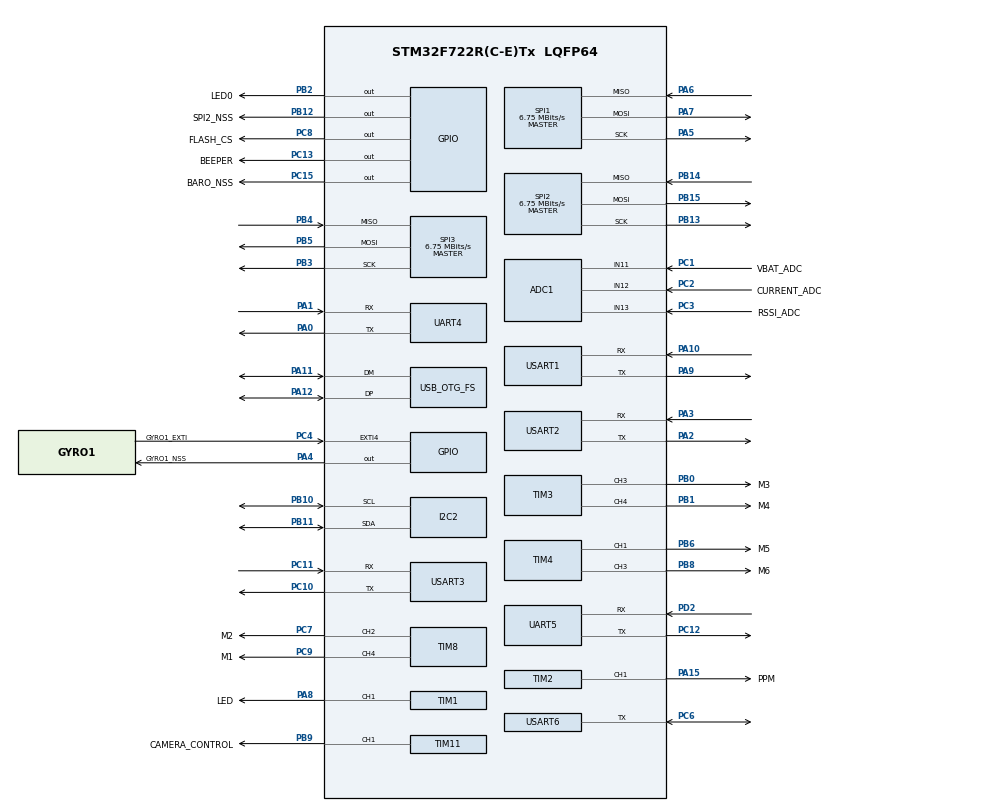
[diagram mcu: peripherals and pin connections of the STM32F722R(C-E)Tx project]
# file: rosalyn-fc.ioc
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ADC1.Channel-1\#ChannelRegularConversion=ADC_CHANNEL_11
ADC1.NbrOfConversionFlag=1
ADC1.Rank-1\#ChannelRegularConversion=1
ADC1.SamplingTime-1\#ChannelRegularConversion=ADC_SAMPLETIME_3CYCLES
ADC1.master=1
CORTEX_M7.ART_ACCLERATOR_ENABLE=1
CORTEX_M7.CPU_DCache=Enabled
CORTEX_M7.CPU_ICache=Enabled
CORTEX_M7.PREFETCH_ENABLE=1
I2C2.Timing=0x20404768
Mcu.Family=STM32F7
Mcu.Name=STM32F722R(C-E)Tx
Mcu.Package=LQFP64
NVIC.OTG_FS_IRQn=true\:0\:0\:false\:false\:true\:false\:true
NVIC.PriorityGroup=NVIC_PRIORITYGROUP_4
PA0-WKUP.Mode=Asynchronous
PA0-WKUP.Signal=UART4_TX
PA1.Mode=Asynchronous
PA1.Signal=UART4_RX
PA10.Mode=Asynchronous
PA10.Signal=USART1_RX
PA11.Mode=Device_Only
PA11.Signal=USB_OTG_FS_DM
PA12.Mode=Device_Only
PA12.Signal=USB_OTG_FS_DP
PA13.Mode=Serial_Wire
PA13.Signal=SYS_JTMS-SWDIO
PA14.Mode=Serial_Wire
PA14.Signal=SYS_JTCK-SWCLK
PA15.GPIO_Label=PPM
PA15.Signal=S_TIM2_CH1_ETR
PA2.Mode=Asynchronous
PA2.Signal=USART2_TX
PA3.Mode=Asynchronous
PA3.Signal=USART2_RX
PA4.GPIO_Label=GYRO1_NSS
PA4.PinState=GPIO_PIN_SET
PA4.Signal=GPIO_Output
PA5.Mode=Full_Duplex_Master
PA5.Signal=SPI1_SCK
PA6.GPIO_PuPd=GPIO_PULLUP
PA6.Mode=Full_Duplex_Master
PA6.Signal=SPI1_MISO
PA7.Mode=Full_Duplex_Master
PA7.Signal=SPI1_MOSI
PA8.GPIO_Label=LED
PA8.Signal=S_TIM1_CH1
PA9.Mode=Asynchronous
PA9.Signal=USART1_TX
PB0.GPIO_Label=M3
PB0.Signal=S_TIM3_CH3
PB1.GPIO_Label=M4
PB1.Signal=S_TIM3_CH4
PB10.Mode=I2C
PB10.Signal=I2C2_SCL
PB11.Mode=I2C
PB11.Signal=I2C2_SDA
PB12.GPIO_Label=SPI2_NSS
PB12.PinState=GPIO_PIN_SET
PB12.Signal=GPIO_Output
PB13.Mode=Full_Duplex_Master
PB13.Signal=SPI2_SCK
PB14.GPIO_PuPd=GPIO_PULLUP
PB14.Mode=Full_Duplex_Master
PB14.Signal=SPI2_MISO
PB15.Mode=Full_Duplex_Master
PB15.Signal=SPI2_MOSI
PB2.GPIO_Label=LED0
PB2.PinState=GPIO_PIN_SET
PB2.Signal=GPIO_Output
PB3.Mode=Full_Duplex_Master
PB3.Signal=SPI3_SCK
PB4.GPIO_PuPd=GPIO_PULLUP
PB4.Mode=Full_Duplex_Master
PB4.Signal=SPI3_MISO
PB5.Mode=Full_Duplex_Master
PB5.Signal=SPI3_MOSI
PB6.GPIO_Label=M5
PB6.Signal=S_TIM4_CH1
PB8.GPIO_Label=M6
PB8.Signal=S_TIM4_CH3
PB9.GPIO_Label=CAMERA_CONTROL
PB9.Signal=S_TIM11_CH1
PC1.GPIO_Label=VBAT_ADC
PC1.Signal=ADCx_IN11
PC10.Mode=Asynchronous
PC10.Signal=USART3_TX
PC11.Mode=Asynchronous
PC11.Signal=USART3_RX
PC12.Mode=Asynchronous
PC12.Signal=UART5_TX
PC13.GPIO_Label=BEEPER
PC13.Signal=GPIO_Output
PC15-OSC32_OUT.GPIO_Label=BARO_NSS
PC15-OSC32_OUT.PinState=GPIO_PIN_SET
PC15-OSC32_OUT.Signal=GPIO_Output
PC2.GPIO_Label=CURRENT_ADC
PC2.Signal=ADCx_IN12
PC3.GPIO_Label=RSSI_ADC
PC3.Signal=ADCx_IN13
PC4.GPIO_Label=GYRO1_EXTI
PC4.Signal=GPXTI4
PC6.Mode=Half_duplex(single_wire_mode)
PC6.Signal=USART6_TX
PC7.GPIO_Label=M2
PC7.Signal=S_TIM8_CH2
PC8.GPIO_Label=FLASH_CS
PC8.PinState=GPIO_PIN_SET
PC8.Signal=GPIO_Output
PC9.GPIO_Label=M1
PC9.Signal=S_TIM8_CH4
PD2.Mode=Asynchronous
PD2.Signal=UART5_RX
PH0-OSC_IN.Mode=HSE-External-Oscillator
PH0-OSC_IN.Signal=RCC_OSC_IN
PH1-OSC_OUT.Mode=HSE-External-Oscillator
PH1-OSC_OUT.Signal=RCC_OSC_OUT
ProjectManager.HeapSize=0x200
ProjectManager.StackSize=0x400
ProjectManager.TargetToolchain=STM32CubeIDE
RCC.AHBFreq_Value=216000000
RCC.APB1CLKDivider=RCC_HCLK_DIV4
RCC.APB1Freq_Value=54000000
RCC.APB1TimFreq_Value=108000000
RCC.APB2CLKDivider=RCC_HCLK_DIV2
RCC.APB2Freq_Value=108000000
RCC.APB2TimFreq_Value=216000000
RCC.CortexFreq_Value=216000000
RCC.HCLKFreq_Value=216000000
RCC.HSE_VALUE=8000000
RCC.HSI_VALUE=16000000
RCC.LSE_VALUE=32768
RCC.PLLM=4
RCC.PLLN=216
RCC.PLLQ=9
RCC.SYSCLKFreq_VALUE=216000000
RCC.SYSCLKSource=RCC_SYSCLKSOURCE_PLLCLK
RCC.USBFreq_Value=48000000
RCC.VCOOutputFreq_Value=432000000
SH.ADCx_IN11.0=ADC1_IN11,IN11
SH.ADCx_IN12.0=ADC1_IN12,IN12
SH.ADCx_IN13.0=ADC1_IN13,IN13
SH.S_TIM11_CH1.0=TIM11_CH1,PWM Generation1 CH1
SH.S_TIM1_CH1.0=TIM1_CH1,PWM Generation1 CH1
SH.S_TIM2_CH1_ETR.0=TIM2_CH1,PWM Generation1 CH1
SH.S_TIM3_CH3.0=TIM3_CH3,PWM Generation3 CH3
SH.S_TIM3_CH4.0=TIM3_CH4,PWM Generation4 CH4
SH.S_TIM4_CH1.0=TIM4_CH1,PWM Generation1 CH1
SH.S_TIM4_CH3.0=TIM4_CH3,PWM Generation3 CH3
SH.S_TIM8_CH2.0=TIM8_CH2,PWM Generation2 CH2
SH.S_TIM8_CH4.0=TIM8_CH4,PWM Generation4 CH4
SPI1.BaudRatePrescaler=SPI_BAUDRATEPRESCALER_16
SPI1.CalculateBaudRate=6.75 MBits/s
SPI1.DataSize=SPI_DATASIZE_8BIT
SPI1.Direction=SPI_DIRECTION_2LINES
SPI1.Mode=SPI_MODE_MASTER
SPI1.VirtualType=VM_MASTER
SPI2.BaudRatePrescaler=SPI_BAUDRATEPRESCALER_8
SPI2.CalculateBaudRate=6.75 MBits/s
SPI2.DataSize=SPI_DATASIZE_8BIT
SPI2.Direction=SPI_DIRECTION_2LINES
SPI2.Mode=SPI_MODE_MASTER
SPI2.VirtualType=VM_MASTER
SPI3.BaudRatePrescaler=SPI_BAUDRATEPRESCALER_8
SPI3.CalculateBaudRate=6.75 MBits/s
SPI3.DataSize=SPI_DATASIZE_8BIT
SPI3.Direction=SPI_DIRECTION_2LINES
SPI3.Mode=SPI_MODE_MASTER
SPI3.VirtualType=VM_MASTER
TIM1.Channel-PWM\ Generation1\ CH1=TIM_CHANNEL_1
TIM11.Channel=TIM_CHANNEL_1
TIM2.Channel-PWM\ Generation1\ CH1=TIM_CHANNEL_1
TIM3.Channel-PWM\ Generation3\ CH3=TIM_CHANNEL_3
TIM3.Channel-PWM\ Generation4\ CH4=TIM_CHANNEL_4
TIM4.Channel-PWM\ Generation1\ CH1=TIM_CHANNEL_1
TIM4.Channel-PWM\ Generation3\ CH3=TIM_CHANNEL_3
TIM8.Channel-PWM\ Generation2\ CH2=TIM_CHANNEL_2
TIM8.Channel-PWM\ Generation4\ CH4=TIM_CHANNEL_4
USART1.VirtualMode-Asynchronous=VM_ASYNC
USART2.VirtualMode-Asynchronous=VM_ASYNC
USART3.VirtualMode-Asynchronous=VM_ASYNC
USART6.VirtualMode=VM_ASYNC
USB_DEVICE.CLASS_NAME_FS=CDC
USB_DEVICE.VirtualMode-CDC_FS=Cdc
USB_DEVICE.VirtualModeFS=Cdc_FS
USB_OTG_FS.VirtualMode=Device_Only
VP_ADC1_TempSens_Input.Mode=IN-TempSens
VP_ADC1_Vref_Input.Mode=IN-Vrefint
VP_TIM11_VS_ClockSourceINT.Mode=Enable_Timer
VP_USB_DEVICE_VS_USB_DEVICE_CDC_FS.Mode=CDC_FS
board=custom

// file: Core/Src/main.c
/* USER CODE BEGIN Header */
/**
  ******************************************************************************
  * @file           : main.c
  * @brief          : Main program body
  ******************************************************************************
  * @attention
  *
  * <h2><center>&copy; Copyright (c) 2020 STMicroelectronics.
  * All rights reserved.</center></h2>
  *
  * This software component is licensed by ST under BSD 3-Clause license,
  * the "License"; You may not use this file except in compliance with the
  * License. You may obtain a copy of the License at:
  *                        opensource.org/licenses/BSD-3-Clause
  *
  ******************************************************************************
  */
/* USER CODE END Header */
#include "main.h"
#include "usb_device.h"

void SystemClock_Config(void);
static void MX_GPIO_Init(void);
static void MX_SPI1_Init(void);
static void MX_SPI2_Init(void);
static void MX_TIM1_Init(void);
static void MX_TIM3_Init(void);
static void MX_TIM4_Init(void);
static void MX_TIM8_Init(void);
static void MX_TIM11_Init(void);
static void MX_UART4_Init(void);
static void MX_UART5_Init(void);
static void MX_USART1_UART_Init(void);
static void MX_ADC1_Init(void);
static void MX_SPI3_Init(void);
static void MX_USART2_UART_Init(void);
static void MX_USART3_UART_Init(void);
static void MX_I2C2_Init(void);
static void MX_TIM2_Init(void);
static void MX_USART6_UART_Init(void);

int main(void)
{

  /* Enable I-Cache---------------------------------------------------------*/
  SCB_EnableICache();

  /* Enable D-Cache---------------------------------------------------------*/
  SCB_EnableDCache();

  /* MCU Configuration--------------------------------------------------------*/

  /* Reset of all peripherals, Initializes the Flash interface and the Systick. */
  HAL_Init();

  /* Configure the system clock */
  SystemClock_Config();

  /* Initialize all configured peripherals */
  MX_GPIO_Init();
  MX_SPI1_Init();
  MX_SPI2_Init();
  MX_TIM1_Init();
  MX_TIM3_Init();
  MX_TIM4_Init();
  MX_TIM8_Init();
  MX_TIM11_Init();
  MX_UART4_Init();
  MX_UART5_Init();
  MX_USART1_UART_Init();
  MX_ADC1_Init();
  MX_SPI3_Init();
  MX_USART2_UART_Init();
  MX_USART3_UART_Init();
  MX_I2C2_Init();
  MX_TIM2_Init();
  MX_USB_DEVICE_Init();
  MX_USART6_UART_Init();
  /* USER CODE BEGIN 2 */
  extern void RosalynFcSetup( void );
  RosalynFcSetup();
  /* USER CODE END 2 */

  /* Infinite loop */
  while (1)
  {

    /* USER CODE BEGIN 3 */
    extern void RosalynFcLoop( void );
    RosalynFcLoop();
  }
  /* USER CODE END 3 */
}

void SystemClock_Config(void)
{
  LL_FLASH_SetLatency(LL_FLASH_LATENCY_7);
  while(LL_FLASH_GetLatency()!= LL_FLASH_LATENCY_7)
  {
  }
  LL_PWR_SetRegulVoltageScaling(LL_PWR_REGU_VOLTAGE_SCALE1);
  LL_PWR_EnableOverDriveMode();
  LL_RCC_HSE_Enable();

   /* Wait till HSE is ready */
  while(LL_RCC_HSE_IsReady() != 1)
  {

  }
  LL_RCC_PLL_ConfigDomain_SYS(LL_RCC_PLLSOURCE_HSE, LL_RCC_PLLM_DIV_4, 216, LL_RCC_PLLP_DIV_2);
  LL_RCC_PLL_ConfigDomain_48M(LL_RCC_PLLSOURCE_HSE, LL_RCC_PLLM_DIV_4, 216, LL_RCC_PLLQ_DIV_9);
  LL_RCC_PLL_Enable();

   /* Wait till PLL is ready */
  while(LL_RCC_PLL_IsReady() != 1)
  {

  }
  LL_RCC_SetAHBPrescaler(LL_RCC_SYSCLK_DIV_1);
  LL_RCC_SetAPB1Prescaler(LL_RCC_APB1_DIV_4);
  LL_RCC_SetAPB2Prescaler(LL_RCC_APB2_DIV_2);
  LL_RCC_SetSysClkSource(LL_RCC_SYS_CLKSOURCE_PLL);

   /* Wait till System clock is ready */
  while(LL_RCC_GetSysClkSource() != LL_RCC_SYS_CLKSOURCE_STATUS_PLL)
  {

  }
  LL_SetSystemCoreClock(216000000);

   /* Update the time base */
  if (HAL_InitTick (TICK_INT_PRIORITY) != HAL_OK)
  {
    Error_Handler();
  }
  LL_RCC_SetUSBClockSource(LL_RCC_USB_CLKSOURCE_PLL);
  LL_RCC_SetUSARTClockSource(LL_RCC_USART1_CLKSOURCE_PCLK2);
  LL_RCC_SetUSARTClockSource(LL_RCC_USART2_CLKSOURCE_PCLK1);
  LL_RCC_SetUSARTClockSource(LL_RCC_USART3_CLKSOURCE_PCLK1);
  LL_RCC_SetUSARTClockSource(LL_RCC_USART6_CLKSOURCE_PCLK2);
  LL_RCC_SetUARTClockSource(LL_RCC_UART4_CLKSOURCE_PCLK1);
  LL_RCC_SetUARTClockSource(LL_RCC_UART5_CLKSOURCE_PCLK1);
  LL_RCC_SetI2CClockSource(LL_RCC_I2C2_CLKSOURCE_PCLK1);
}

static void MX_ADC1_Init(void)
{

  LL_ADC_InitTypeDef ADC_InitStruct = {0};
  LL_ADC_REG_InitTypeDef ADC_REG_InitStruct = {0};
  LL_ADC_CommonInitTypeDef ADC_CommonInitStruct = {0};

  LL_GPIO_InitTypeDef GPIO_InitStruct = {0};

  /* Peripheral clock enable */
  LL_APB2_GRP1_EnableClock(LL_APB2_GRP1_PERIPH_ADC1);

  LL_AHB1_GRP1_EnableClock(LL_AHB1_GRP1_PERIPH_GPIOC);
  /**ADC1 GPIO Configuration
  PC1   ------> ADC1_IN11
  PC2   ------> ADC1_IN12
  PC3   ------> ADC1_IN13
  */
  GPIO_InitStruct.Pin = VBAT_ADC_Pin;
  GPIO_InitStruct.Mode = LL_GPIO_MODE_ANALOG;
  GPIO_InitStruct.Pull = LL_GPIO_PULL_NO;
  LL_GPIO_Init(VBAT_ADC_GPIO_Port, &GPIO_InitStruct);

  GPIO_InitStruct.Pin = CURRENT_ADC_Pin;
  GPIO_InitStruct.Mode = LL_GPIO_MODE_ANALOG;
  GPIO_InitStruct.Pull = LL_GPIO_PULL_NO;
  LL_GPIO_Init(CURRENT_ADC_GPIO_Port, &GPIO_InitStruct);

  GPIO_InitStruct.Pin = RSSI_ADC_Pin;
  GPIO_InitStruct.Mode = LL_GPIO_MODE_ANALOG;
  GPIO_InitStruct.Pull = LL_GPIO_PULL_NO;
  LL_GPIO_Init(RSSI_ADC_GPIO_Port, &GPIO_InitStruct);

  /** Common config
  */
  ADC_InitStruct.Resolution = LL_ADC_RESOLUTION_12B;
  ADC_InitStruct.DataAlignment = LL_ADC_DATA_ALIGN_RIGHT;
  ADC_InitStruct.SequencersScanMode = LL_ADC_SEQ_SCAN_DISABLE;
  LL_ADC_Init(ADC1, &ADC_InitStruct);
  ADC_REG_InitStruct.TriggerSource = LL_ADC_REG_TRIG_SOFTWARE;
  ADC_REG_InitStruct.SequencerLength = LL_ADC_REG_SEQ_SCAN_DISABLE;
  ADC_REG_InitStruct.SequencerDiscont = LL_ADC_REG_SEQ_DISCONT_DISABLE;
  ADC_REG_InitStruct.ContinuousMode = LL_ADC_REG_CONV_SINGLE;
  ADC_REG_InitStruct.DMATransfer = LL_ADC_REG_DMA_TRANSFER_NONE;
  LL_ADC_REG_Init(ADC1, &ADC_REG_InitStruct);
  LL_ADC_REG_SetFlagEndOfConversion(ADC1, LL_ADC_REG_FLAG_EOC_UNITARY_CONV);
  ADC_CommonInitStruct.CommonClock = LL_ADC_CLOCK_SYNC_PCLK_DIV4;
  ADC_CommonInitStruct.Multimode = LL_ADC_MULTI_INDEPENDENT;
  LL_ADC_CommonInit(__LL_ADC_COMMON_INSTANCE(ADC1), &ADC_CommonInitStruct);
  /** Configure Regular Channel
  */
  LL_ADC_REG_SetSequencerRanks(ADC1, LL_ADC_REG_RANK_1, LL_ADC_CHANNEL_11);
  LL_ADC_SetChannelSamplingTime(ADC1, LL_ADC_CHANNEL_11, LL_ADC_SAMPLINGTIME_3CYCLES);

}

static void MX_I2C2_Init(void)
{

  LL_I2C_InitTypeDef I2C_InitStruct = {0};

  LL_GPIO_InitTypeDef GPIO_InitStruct = {0};

  LL_AHB1_GRP1_EnableClock(LL_AHB1_GRP1_PERIPH_GPIOB);
  /**I2C2 GPIO Configuration
  PB10   ------> I2C2_SCL
  PB11   ------> I2C2_SDA
  */
  GPIO_InitStruct.Pin = LL_GPIO_PIN_10;
  GPIO_InitStruct.Mode = LL_GPIO_MODE_ALTERNATE;
  GPIO_InitStruct.Speed = LL_GPIO_SPEED_FREQ_VERY_HIGH;
  GPIO_InitStruct.OutputType = LL_GPIO_OUTPUT_OPENDRAIN;
  GPIO_InitStruct.Pull = LL_GPIO_PULL_UP;
  GPIO_InitStruct.Alternate = LL_GPIO_AF_4;
  LL_GPIO_Init(GPIOB, &GPIO_InitStruct);

  GPIO_InitStruct.Pin = LL_GPIO_PIN_11;
  GPIO_InitStruct.Mode = LL_GPIO_MODE_ALTERNATE;
  GPIO_InitStruct.Speed = LL_GPIO_SPEED_FREQ_VERY_HIGH;
  GPIO_InitStruct.OutputType = LL_GPIO_OUTPUT_OPENDRAIN;
  GPIO_InitStruct.Pull = LL_GPIO_PULL_UP;
  GPIO_InitStruct.Alternate = LL_GPIO_AF_4;
  LL_GPIO_Init(GPIOB, &GPIO_InitStruct);

  /* Peripheral clock enable */
  LL_APB1_GRP1_EnableClock(LL_APB1_GRP1_PERIPH_I2C2);

  /** I2C Initialization
  */
  LL_I2C_EnableAutoEndMode(I2C2);
  LL_I2C_SetOwnAddress2(I2C2, 0, LL_I2C_OWNADDRESS2_NOMASK);
  LL_I2C_DisableOwnAddress2(I2C2);
  LL_I2C_DisableGeneralCall(I2C2);
  LL_I2C_EnableClockStretching(I2C2);
  I2C_InitStruct.PeripheralMode = LL_I2C_MODE_I2C;
  I2C_InitStruct.Timing = 0x20404768;
  I2C_InitStruct.AnalogFilter = LL_I2C_ANALOGFILTER_ENABLE;
  I2C_InitStruct.DigitalFilter = 0;
  I2C_InitStruct.OwnAddress1 = 0;
  I2C_InitStruct.TypeAcknowledge = LL_I2C_ACK;
  I2C_InitStruct.OwnAddrSize = LL_I2C_OWNADDRESS1_7BIT;
  LL_I2C_Init(I2C2, &I2C_InitStruct);

}

static void MX_SPI1_Init(void)
{

  LL_SPI_InitTypeDef SPI_InitStruct = {0};

  LL_GPIO_InitTypeDef GPIO_InitStruct = {0};

  /* Peripheral clock enable */
  LL_APB2_GRP1_EnableClock(LL_APB2_GRP1_PERIPH_SPI1);

  LL_AHB1_GRP1_EnableClock(LL_AHB1_GRP1_PERIPH_GPIOA);
  /**SPI1 GPIO Configuration
  PA5   ------> SPI1_SCK
  PA6   ------> SPI1_MISO
  PA7   ------> SPI1_MOSI
  */
  GPIO_InitStruct.Pin = LL_GPIO_PIN_5;
  GPIO_InitStruct.Mode = LL_GPIO_MODE_ALTERNATE;
  GPIO_InitStruct.Speed = LL_GPIO_SPEED_FREQ_VERY_HIGH;
  GPIO_InitStruct.OutputType = LL_GPIO_OUTPUT_PUSHPULL;
  GPIO_InitStruct.Pull = LL_GPIO_PULL_NO;
  GPIO_InitStruct.Alternate = LL_GPIO_AF_5;
  LL_GPIO_Init(GPIOA, &GPIO_InitStruct);

  GPIO_InitStruct.Pin = LL_GPIO_PIN_6;
  GPIO_InitStruct.Mode = LL_GPIO_MODE_ALTERNATE;
  GPIO_InitStruct.Speed = LL_GPIO_SPEED_FREQ_VERY_HIGH;
  GPIO_InitStruct.OutputType = LL_GPIO_OUTPUT_PUSHPULL;
  GPIO_InitStruct.Pull = LL_GPIO_PULL_UP;
  GPIO_InitStruct.Alternate = LL_GPIO_AF_5;
  LL_GPIO_Init(GPIOA, &GPIO_InitStruct);

  GPIO_InitStruct.Pin = LL_GPIO_PIN_7;
  GPIO_InitStruct.Mode = LL_GPIO_MODE_ALTERNATE;
  GPIO_InitStruct.Speed = LL_GPIO_SPEED_FREQ_VERY_HIGH;
  GPIO_InitStruct.OutputType = LL_GPIO_OUTPUT_PUSHPULL;
  GPIO_InitStruct.Pull = LL_GPIO_PULL_NO;
  GPIO_InitStruct.Alternate = LL_GPIO_AF_5;
  LL_GPIO_Init(GPIOA, &GPIO_InitStruct);

  /* SPI1 parameter configuration*/
  SPI_InitStruct.TransferDirection = LL_SPI_FULL_DUPLEX;
  SPI_InitStruct.Mode = LL_SPI_MODE_MASTER;
  SPI_InitStruct.DataWidth = LL_SPI_DATAWIDTH_8BIT;
  SPI_InitStruct.ClockPolarity = LL_SPI_POLARITY_LOW;
  SPI_InitStruct.ClockPhase = LL_SPI_PHASE_1EDGE;
  SPI_InitStruct.NSS = LL_SPI_NSS_SOFT;
  SPI_InitStruct.BaudRate = LL_SPI_BAUDRATEPRESCALER_DIV16;
  SPI_InitStruct.BitOrder = LL_SPI_MSB_FIRST;
  SPI_InitStruct.CRCCalculation = LL_SPI_CRCCALCULATION_DISABLE;
  SPI_InitStruct.CRCPoly = 7;
  LL_SPI_Init(SPI1, &SPI_InitStruct);
  LL_SPI_SetStandard(SPI1, LL_SPI_PROTOCOL_MOTOROLA);
  LL_SPI_EnableNSSPulseMgt(SPI1);

}

static void MX_SPI2_Init(void)
{

  LL_SPI_InitTypeDef SPI_InitStruct = {0};

  LL_GPIO_InitTypeDef GPIO_InitStruct = {0};

  /* Peripheral clock enable */
  LL_APB1_GRP1_EnableClock(LL_APB1_GRP1_PERIPH_SPI2);

  LL_AHB1_GRP1_EnableClock(LL_AHB1_GRP1_PERIPH_GPIOB);
  /**SPI2 GPIO Configuration
  PB13   ------> SPI2_SCK
  PB14   ------> SPI2_MISO
  PB15   ------> SPI2_MOSI
  */
  GPIO_InitStruct.Pin = LL_GPIO_PIN_13;
  GPIO_InitStruct.Mode = LL_GPIO_MODE_ALTERNATE;
  GPIO_InitStruct.Speed = LL_GPIO_SPEED_FREQ_VERY_HIGH;
  GPIO_InitStruct.OutputType = LL_GPIO_OUTPUT_PUSHPULL;
  GPIO_InitStruct.Pull = LL_GPIO_PULL_NO;
  GPIO_InitStruct.Alternate = LL_GPIO_AF_5;
  LL_GPIO_Init(GPIOB, &GPIO_InitStruct);

  GPIO_InitStruct.Pin = LL_GPIO_PIN_14;
  GPIO_InitStruct.Mode = LL_GPIO_MODE_ALTERNATE;
  GPIO_InitStruct.Speed = LL_GPIO_SPEED_FREQ_VERY_HIGH;
  GPIO_InitStruct.OutputType = LL_GPIO_OUTPUT_PUSHPULL;
  GPIO_InitStruct.Pull = LL_GPIO_PULL_UP;
  GPIO_InitStruct.Alternate = LL_GPIO_AF_5;
  LL_GPIO_Init(GPIOB, &GPIO_InitStruct);

  GPIO_InitStruct.Pin = LL_GPIO_PIN_15;
  GPIO_InitStruct.Mode = LL_GPIO_MODE_ALTERNATE;
  GPIO_InitStruct.Speed = LL_GPIO_SPEED_FREQ_VERY_HIGH;
  GPIO_InitStruct.OutputType = LL_GPIO_OUTPUT_PUSHPULL;
  GPIO_InitStruct.Pull = LL_GPIO_PULL_NO;
  GPIO_InitStruct.Alternate = LL_GPIO_AF_5;
  LL_GPIO_Init(GPIOB, &GPIO_InitStruct);

  /* SPI2 parameter configuration*/
  SPI_InitStruct.TransferDirection = LL_SPI_FULL_DUPLEX;
  SPI_InitStruct.Mode = LL_SPI_MODE_MASTER;
  SPI_InitStruct.DataWidth = LL_SPI_DATAWIDTH_8BIT;
  SPI_InitStruct.ClockPolarity = LL_SPI_POLARITY_LOW;
  SPI_InitStruct.ClockPhase = LL_SPI_PHASE_1EDGE;
  SPI_InitStruct.NSS = LL_SPI_NSS_SOFT;
  SPI_InitStruct.BaudRate = LL_SPI_BAUDRATEPRESCALER_DIV8;
  SPI_InitStruct.BitOrder = LL_SPI_MSB_FIRST;
  SPI_InitStruct.CRCCalculation = LL_SPI_CRCCALCULATION_DISABLE;
  SPI_InitStruct.CRCPoly = 7;
  LL_SPI_Init(SPI2, &SPI_InitStruct);
  LL_SPI_SetStandard(SPI2, LL_SPI_PROTOCOL_MOTOROLA);
  LL_SPI_EnableNSSPulseMgt(SPI2);

}

static void MX_SPI3_Init(void)
{

  LL_SPI_InitTypeDef SPI_InitStruct = {0};

  LL_GPIO_InitTypeDef GPIO_InitStruct = {0};

  /* Peripheral clock enable */
  LL_APB1_GRP1_EnableClock(LL_APB1_GRP1_PERIPH_SPI3);

  LL_AHB1_GRP1_EnableClock(LL_AHB1_GRP1_PERIPH_GPIOB);
  /**SPI3 GPIO Configuration
  PB3   ------> SPI3_SCK
  PB4   ------> SPI3_MISO
  PB5   ------> SPI3_MOSI
  */
  GPIO_InitStruct.Pin = LL_GPIO_PIN_3;
  GPIO_InitStruct.Mode = LL_GPIO_MODE_ALTERNATE;
  GPIO_InitStruct.Speed = LL_GPIO_SPEED_FREQ_VERY_HIGH;
  GPIO_InitStruct.OutputType = LL_GPIO_OUTPUT_PUSHPULL;
  GPIO_InitStruct.Pull = LL_GPIO_PULL_NO;
  GPIO_InitStruct.Alternate = LL_GPIO_AF_6;
  LL_GPIO_Init(GPIOB, &GPIO_InitStruct);

  GPIO_InitStruct.Pin = LL_GPIO_PIN_4;
  GPIO_InitStruct.Mode = LL_GPIO_MODE_ALTERNATE;
  GPIO_InitStruct.Speed = LL_GPIO_SPEED_FREQ_VERY_HIGH;
  GPIO_InitStruct.OutputType = LL_GPIO_OUTPUT_PUSHPULL;
  GPIO_InitStruct.Pull = LL_GPIO_PULL_UP;
  GPIO_InitStruct.Alternate = LL_GPIO_AF_6;
  LL_GPIO_Init(GPIOB, &GPIO_InitStruct);

  GPIO_InitStruct.Pin = LL_GPIO_PIN_5;
  GPIO_InitStruct.Mode = LL_GPIO_MODE_ALTERNATE;
  GPIO_InitStruct.Speed = LL_GPIO_SPEED_FREQ_VERY_HIGH;
  GPIO_InitStruct.OutputType = LL_GPIO_OUTPUT_PUSHPULL;
  GPIO_InitStruct.Pull = LL_GPIO_PULL_NO;
  GPIO_InitStruct.Alternate = LL_GPIO_AF_6;
  LL_GPIO_Init(GPIOB, &GPIO_InitStruct);

  /* SPI3 parameter configuration*/
  SPI_InitStruct.TransferDirection = LL_SPI_FULL_DUPLEX;
  SPI_InitStruct.Mode = LL_SPI_MODE_MASTER;
  SPI_InitStruct.DataWidth = LL_SPI_DATAWIDTH_8BIT;
  SPI_InitStruct.ClockPolarity = LL_SPI_POLARITY_LOW;
  SPI_InitStruct.ClockPhase = LL_SPI_PHASE_1EDGE;
  SPI_InitStruct.NSS = LL_SPI_NSS_SOFT;
  SPI_InitStruct.BaudRate = LL_SPI_BAUDRATEPRESCALER_DIV8;
  SPI_InitStruct.BitOrder = LL_SPI_MSB_FIRST;
  SPI_InitStruct.CRCCalculation = LL_SPI_CRCCALCULATION_DISABLE;
  SPI_InitStruct.CRCPoly = 7;
  LL_SPI_Init(SPI3, &SPI_InitStruct);
  LL_SPI_SetStandard(SPI3, LL_SPI_PROTOCOL_MOTOROLA);
  LL_SPI_EnableNSSPulseMgt(SPI3);

}

static void MX_TIM1_Init(void)
{

  LL_TIM_InitTypeDef TIM_InitStruct = {0};
  LL_TIM_OC_InitTypeDef TIM_OC_InitStruct = {0};
  LL_TIM_BDTR_InitTypeDef TIM_BDTRInitStruct = {0};

  LL_GPIO_InitTypeDef GPIO_InitStruct = {0};

  /* Peripheral clock enable */
  LL_APB2_GRP1_EnableClock(LL_APB2_GRP1_PERIPH_TIM1);

  TIM_InitStruct.Prescaler = 0;
  TIM_InitStruct.CounterMode = LL_TIM_COUNTERMODE_UP;
  TIM_InitStruct.Autoreload = 65535;
  TIM_InitStruct.ClockDivision = LL_TIM_CLOCKDIVISION_DIV1;
  TIM_InitStruct.RepetitionCounter = 0;
  LL_TIM_Init(TIM1, &TIM_InitStruct);
  LL_TIM_DisableARRPreload(TIM1);
  LL_TIM_OC_EnablePreload(TIM1, LL_TIM_CHANNEL_CH1);
  TIM_OC_InitStruct.OCMode = LL_TIM_OCMODE_PWM1;
  TIM_OC_InitStruct.OCState = LL_TIM_OCSTATE_DISABLE;
  TIM_OC_InitStruct.OCNState = LL_TIM_OCSTATE_DISABLE;
  TIM_OC_InitStruct.CompareValue = 0;
  TIM_OC_InitStruct.OCPolarity = LL_TIM_OCPOLARITY_HIGH;
  TIM_OC_InitStruct.OCNPolarity = LL_TIM_OCPOLARITY_HIGH;
  TIM_OC_InitStruct.OCIdleState = LL_TIM_OCIDLESTATE_LOW;
  TIM_OC_InitStruct.OCNIdleState = LL_TIM_OCIDLESTATE_LOW;
  LL_TIM_OC_Init(TIM1, LL_TIM_CHANNEL_CH1, &TIM_OC_InitStruct);
  LL_TIM_OC_DisableFast(TIM1, LL_TIM_CHANNEL_CH1);
  LL_TIM_SetTriggerOutput(TIM1, LL_TIM_TRGO_RESET);
  LL_TIM_SetTriggerOutput2(TIM1, LL_TIM_TRGO2_RESET);
  LL_TIM_DisableMasterSlaveMode(TIM1);
  TIM_BDTRInitStruct.OSSRState = LL_TIM_OSSR_DISABLE;
  TIM_BDTRInitStruct.OSSIState = LL_TIM_OSSI_DISABLE;
  TIM_BDTRInitStruct.LockLevel = LL_TIM_LOCKLEVEL_OFF;
  TIM_BDTRInitStruct.DeadTime = 0;
  TIM_BDTRInitStruct.BreakState = LL_TIM_BREAK_DISABLE;
  TIM_BDTRInitStruct.BreakPolarity = LL_TIM_BREAK_POLARITY_HIGH;
  TIM_BDTRInitStruct.BreakFilter = LL_TIM_BREAK_FILTER_FDIV1;
  TIM_BDTRInitStruct.Break2State = LL_TIM_BREAK2_DISABLE;
  TIM_BDTRInitStruct.Break2Polarity = LL_TIM_BREAK2_POLARITY_HIGH;
  TIM_BDTRInitStruct.Break2Filter = LL_TIM_BREAK2_FILTER_FDIV1;
  TIM_BDTRInitStruct.AutomaticOutput = LL_TIM_AUTOMATICOUTPUT_DISABLE;
  LL_TIM_BDTR_Init(TIM1, &TIM_BDTRInitStruct);
  LL_AHB1_GRP1_EnableClock(LL_AHB1_GRP1_PERIPH_GPIOA);
  /**TIM1 GPIO Configuration
  PA8   ------> TIM1_CH1
  */
  GPIO_InitStruct.Pin = LED_Pin;
  GPIO_InitStruct.Mode = LL_GPIO_MODE_ALTERNATE;
  GPIO_InitStruct.Speed = LL_GPIO_SPEED_FREQ_LOW;
  GPIO_InitStruct.OutputType = LL_GPIO_OUTPUT_PUSHPULL;
  GPIO_InitStruct.Pull = LL_GPIO_PULL_NO;
  GPIO_InitStruct.Alternate = LL_GPIO_AF_1;
  LL_GPIO_Init(LED_GPIO_Port, &GPIO_InitStruct);

}

static void MX_TIM2_Init(void)
{

  LL_TIM_InitTypeDef TIM_InitStruct = {0};
  LL_TIM_OC_InitTypeDef TIM_OC_InitStruct = {0};

  LL_GPIO_InitTypeDef GPIO_InitStruct = {0};

  /* Peripheral clock enable */
  LL_APB1_GRP1_EnableClock(LL_APB1_GRP1_PERIPH_TIM2);

  TIM_InitStruct.Prescaler = 0;
  TIM_InitStruct.CounterMode = LL_TIM_COUNTERMODE_UP;
  TIM_InitStruct.Autoreload = 4294967295;
  TIM_InitStruct.ClockDivision = LL_TIM_CLOCKDIVISION_DIV1;
  LL_TIM_Init(TIM2, &TIM_InitStruct);
  LL_TIM_DisableARRPreload(TIM2);
  LL_TIM_OC_EnablePreload(TIM2, LL_TIM_CHANNEL_CH1);
  TIM_OC_InitStruct.OCMode = LL_TIM_OCMODE_PWM1;
  TIM_OC_InitStruct.OCState = LL_TIM_OCSTATE_DISABLE;
  TIM_OC_InitStruct.OCNState = LL_TIM_OCSTATE_DISABLE;
  TIM_OC_InitStruct.CompareValue = 0;
  TIM_OC_InitStruct.OCPolarity = LL_TIM_OCPOLARITY_HIGH;
  LL_TIM_OC_Init(TIM2, LL_TIM_CHANNEL_CH1, &TIM_OC_InitStruct);
  LL_TIM_OC_DisableFast(TIM2, LL_TIM_CHANNEL_CH1);
  LL_TIM_SetTriggerOutput(TIM2, LL_TIM_TRGO_RESET);
  LL_TIM_DisableMasterSlaveMode(TIM2);
  LL_AHB1_GRP1_EnableClock(LL_AHB1_GRP1_PERIPH_GPIOA);
  /**TIM2 GPIO Configuration
  PA15   ------> TIM2_CH1
  */
  GPIO_InitStruct.Pin = PPM_Pin;
  GPIO_InitStruct.Mode = LL_GPIO_MODE_ALTERNATE;
  GPIO_InitStruct.Speed = LL_GPIO_SPEED_FREQ_LOW;
  GPIO_InitStruct.OutputType = LL_GPIO_OUTPUT_PUSHPULL;
  GPIO_InitStruct.Pull = LL_GPIO_PULL_NO;
  GPIO_InitStruct.Alternate = LL_GPIO_AF_1;
  LL_GPIO_Init(PPM_GPIO_Port, &GPIO_InitStruct);

}

static void MX_TIM3_Init(void)
{

  LL_TIM_InitTypeDef TIM_InitStruct = {0};
  LL_TIM_OC_InitTypeDef TIM_OC_InitStruct = {0};

  LL_GPIO_InitTypeDef GPIO_InitStruct = {0};

  /* Peripheral clock enable */
  LL_APB1_GRP1_EnableClock(LL_APB1_GRP1_PERIPH_TIM3);

  TIM_InitStruct.Prescaler = 0;
  TIM_InitStruct.CounterMode = LL_TIM_COUNTERMODE_UP;
  TIM_InitStruct.Autoreload = 65535;
  TIM_InitStruct.ClockDivision = LL_TIM_CLOCKDIVISION_DIV1;
  LL_TIM_Init(TIM3, &TIM_InitStruct);
  LL_TIM_DisableARRPreload(TIM3);
  LL_TIM_OC_EnablePreload(TIM3, LL_TIM_CHANNEL_CH3);
  TIM_OC_InitStruct.OCMode = LL_TIM_OCMODE_PWM1;
  TIM_OC_InitStruct.OCState = LL_TIM_OCSTATE_DISABLE;
  TIM_OC_InitStruct.OCNState = LL_TIM_OCSTATE_DISABLE;
  TIM_OC_InitStruct.CompareValue = 0;
  TIM_OC_InitStruct.OCPolarity = LL_TIM_OCPOLARITY_HIGH;
  LL_TIM_OC_Init(TIM3, LL_TIM_CHANNEL_CH3, &TIM_OC_InitStruct);
  LL_TIM_OC_DisableFast(TIM3, LL_TIM_CHANNEL_CH3);
  LL_TIM_OC_EnablePreload(TIM3, LL_TIM_CHANNEL_CH4);
  TIM_OC_InitStruct.OCState = LL_TIM_OCSTATE_DISABLE;
  TIM_OC_InitStruct.OCNState = LL_TIM_OCSTATE_DISABLE;
  LL_TIM_OC_Init(TIM3, LL_TIM_CHANNEL_CH4, &TIM_OC_InitStruct);
  LL_TIM_OC_DisableFast(TIM3, LL_TIM_CHANNEL_CH4);
  LL_TIM_SetTriggerOutput(TIM3, LL_TIM_TRGO_RESET);
  LL_TIM_DisableMasterSlaveMode(TIM3);
  LL_AHB1_GRP1_EnableClock(LL_AHB1_GRP1_PERIPH_GPIOB);
  /**TIM3 GPIO Configuration
  PB0   ------> TIM3_CH3
  PB1   ------> TIM3_CH4
  */
  GPIO_InitStruct.Pin = M3_Pin;
  GPIO_InitStruct.Mode = LL_GPIO_MODE_ALTERNATE;
  GPIO_InitStruct.Speed = LL_GPIO_SPEED_FREQ_LOW;
  GPIO_InitStruct.OutputType = LL_GPIO_OUTPUT_PUSHPULL;
  GPIO_InitStruct.Pull = LL_GPIO_PULL_NO;
  GPIO_InitStruct.Alternate = LL_GPIO_AF_2;
  LL_GPIO_Init(M3_GPIO_Port, &GPIO_InitStruct);

  GPIO_InitStruct.Pin = M4_Pin;
  GPIO_InitStruct.Mode = LL_GPIO_MODE_ALTERNATE;
  GPIO_InitStruct.Speed = LL_GPIO_SPEED_FREQ_LOW;
  GPIO_InitStruct.OutputType = LL_GPIO_OUTPUT_PUSHPULL;
  GPIO_InitStruct.Pull = LL_GPIO_PULL_NO;
  GPIO_InitStruct.Alternate = LL_GPIO_AF_2;
  LL_GPIO_Init(M4_GPIO_Port, &GPIO_InitStruct);

}

static void MX_TIM4_Init(void)
{

  LL_TIM_InitTypeDef TIM_InitStruct = {0};
  LL_TIM_OC_InitTypeDef TIM_OC_InitStruct = {0};

  LL_GPIO_InitTypeDef GPIO_InitStruct = {0};

  /* Peripheral clock enable */
  LL_APB1_GRP1_EnableClock(LL_APB1_GRP1_PERIPH_TIM4);

  TIM_InitStruct.Prescaler = 0;
  TIM_InitStruct.CounterMode = LL_TIM_COUNTERMODE_UP;
  TIM_InitStruct.Autoreload = 65535;
  TIM_InitStruct.ClockDivision = LL_TIM_CLOCKDIVISION_DIV1;
  LL_TIM_Init(TIM4, &TIM_InitStruct);
  LL_TIM_DisableARRPreload(TIM4);
  LL_TIM_OC_EnablePreload(TIM4, LL_TIM_CHANNEL_CH1);
  TIM_OC_InitStruct.OCMode = LL_TIM_OCMODE_PWM1;
  TIM_OC_InitStruct.OCState = LL_TIM_OCSTATE_DISABLE;
  TIM_OC_InitStruct.OCNState = LL_TIM_OCSTATE_DISABLE;
  TIM_OC_InitStruct.CompareValue = 0;
  TIM_OC_InitStruct.OCPolarity = LL_TIM_OCPOLARITY_HIGH;
  LL_TIM_OC_Init(TIM4, LL_TIM_CHANNEL_CH1, &TIM_OC_InitStruct);
  LL_TIM_OC_DisableFast(TIM4, LL_TIM_CHANNEL_CH1);
  LL_TIM_OC_EnablePreload(TIM4, LL_TIM_CHANNEL_CH3);
  TIM_OC_InitStruct.OCState = LL_TIM_OCSTATE_DISABLE;
  TIM_OC_InitStruct.OCNState = LL_TIM_OCSTATE_DISABLE;
  LL_TIM_OC_Init(TIM4, LL_TIM_CHANNEL_CH3, &TIM_OC_InitStruct);
  LL_TIM_OC_DisableFast(TIM4, LL_TIM_CHANNEL_CH3);
  LL_TIM_SetTriggerOutput(TIM4, LL_TIM_TRGO_RESET);
  LL_TIM_DisableMasterSlaveMode(TIM4);
  LL_AHB1_GRP1_EnableClock(LL_AHB1_GRP1_PERIPH_GPIOB);
  /**TIM4 GPIO Configuration
  PB6   ------> TIM4_CH1
  PB8   ------> TIM4_CH3
  */
  GPIO_InitStruct.Pin = M5_Pin;
  GPIO_InitStruct.Mode = LL_GPIO_MODE_ALTERNATE;
  GPIO_InitStruct.Speed = LL_GPIO_SPEED_FREQ_LOW;
  GPIO_InitStruct.OutputType = LL_GPIO_OUTPUT_PUSHPULL;
  GPIO_InitStruct.Pull = LL_GPIO_PULL_NO;
  GPIO_InitStruct.Alternate = LL_GPIO_AF_2;
  LL_GPIO_Init(M5_GPIO_Port, &GPIO_InitStruct);

  GPIO_InitStruct.Pin = M6_Pin;
  GPIO_InitStruct.Mode = LL_GPIO_MODE_ALTERNATE;
  GPIO_InitStruct.Speed = LL_GPIO_SPEED_FREQ_LOW;
  GPIO_InitStruct.OutputType = LL_GPIO_OUTPUT_PUSHPULL;
  GPIO_InitStruct.Pull = LL_GPIO_PULL_NO;
  GPIO_InitStruct.Alternate = LL_GPIO_AF_2;
  LL_GPIO_Init(M6_GPIO_Port, &GPIO_InitStruct);

}

static void MX_TIM8_Init(void)
{

  LL_TIM_InitTypeDef TIM_InitStruct = {0};
  LL_TIM_OC_InitTypeDef TIM_OC_InitStruct = {0};
  LL_TIM_BDTR_InitTypeDef TIM_BDTRInitStruct = {0};

  LL_GPIO_InitTypeDef GPIO_InitStruct = {0};

  /* Peripheral clock enable */
  LL_APB2_GRP1_EnableClock(LL_APB2_GRP1_PERIPH_TIM8);

  TIM_InitStruct.Prescaler = 0;
  TIM_InitStruct.CounterMode = LL_TIM_COUNTERMODE_UP;
  TIM_InitStruct.Autoreload = 65535;
  TIM_InitStruct.ClockDivision = LL_TIM_CLOCKDIVISION_DIV1;
  TIM_InitStruct.RepetitionCounter = 0;
  LL_TIM_Init(TIM8, &TIM_InitStruct);
  LL_TIM_DisableARRPreload(TIM8);
  LL_TIM_OC_EnablePreload(TIM8, LL_TIM_CHANNEL_CH2);
  TIM_OC_InitStruct.OCMode = LL_TIM_OCMODE_PWM1;
  TIM_OC_InitStruct.OCState = LL_TIM_OCSTATE_DISABLE;
  TIM_OC_InitStruct.OCNState = LL_TIM_OCSTATE_DISABLE;
  TIM_OC_InitStruct.CompareValue = 0;
  TIM_OC_InitStruct.OCPolarity = LL_TIM_OCPOLARITY_HIGH;
  TIM_OC_InitStruct.OCNPolarity = LL_TIM_OCPOLARITY_HIGH;
  TIM_OC_InitStruct.OCIdleState = LL_TIM_OCIDLESTATE_LOW;
  TIM_OC_InitStruct.OCNIdleState = LL_TIM_OCIDLESTATE_LOW;
  LL_TIM_OC_Init(TIM8, LL_TIM_CHANNEL_CH2, &TIM_OC_InitStruct);
  LL_TIM_OC_DisableFast(TIM8, LL_TIM_CHANNEL_CH2);
  LL_TIM_OC_EnablePreload(TIM8, LL_TIM_CHANNEL_CH4);
  TIM_OC_InitStruct.OCState = LL_TIM_OCSTATE_DISABLE;
  TIM_OC_InitStruct.OCNState = LL_TIM_OCSTATE_DISABLE;
  LL_TIM_OC_Init(TIM8, LL_TIM_CHANNEL_CH4, &TIM_OC_InitStruct);
  LL_TIM_OC_DisableFast(TIM8, LL_TIM_CHANNEL_CH4);
  LL_TIM_SetTriggerOutput(TIM8, LL_TIM_TRGO_RESET);
  LL_TIM_SetTriggerOutput2(TIM8, LL_TIM_TRGO2_RESET);
  LL_TIM_DisableMasterSlaveMode(TIM8);
  TIM_BDTRInitStruct.OSSRState = LL_TIM_OSSR_DISABLE;
  TIM_BDTRInitStruct.OSSIState = LL_TIM_OSSI_DISABLE;
  TIM_BDTRInitStruct.LockLevel = LL_TIM_LOCKLEVEL_OFF;
  TIM_BDTRInitStruct.DeadTime = 0;
  TIM_BDTRInitStruct.BreakState = LL_TIM_BREAK_DISABLE;
  TIM_BDTRInitStruct.BreakPolarity = LL_TIM_BREAK_POLARITY_HIGH;
  TIM_BDTRInitStruct.BreakFilter = LL_TIM_BREAK_FILTER_FDIV1;
  TIM_BDTRInitStruct.Break2State = LL_TIM_BREAK2_DISABLE;
  TIM_BDTRInitStruct.Break2Polarity = LL_TIM_BREAK2_POLARITY_HIGH;
  TIM_BDTRInitStruct.Break2Filter = LL_TIM_BREAK2_FILTER_FDIV1;
  TIM_BDTRInitStruct.AutomaticOutput = LL_TIM_AUTOMATICOUTPUT_DISABLE;
  LL_TIM_BDTR_Init(TIM8, &TIM_BDTRInitStruct);
  LL_AHB1_GRP1_EnableClock(LL_AHB1_GRP1_PERIPH_GPIOC);
  /**TIM8 GPIO Configuration
  PC7   ------> TIM8_CH2
  PC9   ------> TIM8_CH4
  */
  GPIO_InitStruct.Pin = M2_Pin;
  GPIO_InitStruct.Mode = LL_GPIO_MODE_ALTERNATE;
  GPIO_InitStruct.Speed = LL_GPIO_SPEED_FREQ_LOW;
  GPIO_InitStruct.OutputType = LL_GPIO_OUTPUT_PUSHPULL;
  GPIO_InitStruct.Pull = LL_GPIO_PULL_NO;
  GPIO_InitStruct.Alternate = LL_GPIO_AF_3;
  LL_GPIO_Init(M2_GPIO_Port, &GPIO_InitStruct);

  GPIO_InitStruct.Pin = M1_Pin;
  GPIO_InitStruct.Mode = LL_GPIO_MODE_ALTERNATE;
  GPIO_InitStruct.Speed = LL_GPIO_SPEED_FREQ_LOW;
  GPIO_InitStruct.OutputType = LL_GPIO_OUTPUT_PUSHPULL;
  GPIO_InitStruct.Pull = LL_GPIO_PULL_NO;
  GPIO_InitStruct.Alternate = LL_GPIO_AF_3;
  LL_GPIO_Init(M1_GPIO_Port, &GPIO_InitStruct);

}

static void MX_TIM11_Init(void)
{

  LL_TIM_InitTypeDef TIM_InitStruct = {0};
  LL_TIM_OC_InitTypeDef TIM_OC_InitStruct = {0};

  LL_GPIO_InitTypeDef GPIO_InitStruct = {0};

  /* Peripheral clock enable */
  LL_APB2_GRP1_EnableClock(LL_APB2_GRP1_PERIPH_TIM11);

  TIM_InitStruct.Prescaler = 0;
  TIM_InitStruct.CounterMode = LL_TIM_COUNTERMODE_UP;
  TIM_InitStruct.Autoreload = 65535;
  TIM_InitStruct.ClockDivision = LL_TIM_CLOCKDIVISION_DIV1;
  LL_TIM_Init(TIM11, &TIM_InitStruct);
  LL_TIM_DisableARRPreload(TIM11);
  LL_TIM_OC_EnablePreload(TIM11, LL_TIM_CHANNEL_CH1);
  TIM_OC_InitStruct.OCMode = LL_TIM_OCMODE_PWM1;
  TIM_OC_InitStruct.OCState = LL_TIM_OCSTATE_DISABLE;
  TIM_OC_InitStruct.OCNState = LL_TIM_OCSTATE_DISABLE;
  TIM_OC_InitStruct.CompareValue = 0;
  TIM_OC_InitStruct.OCPolarity = LL_TIM_OCPOLARITY_HIGH;
  LL_TIM_OC_Init(TIM11, LL_TIM_CHANNEL_CH1, &TIM_OC_InitStruct);
  LL_TIM_OC_DisableFast(TIM11, LL_TIM_CHANNEL_CH1);
  LL_AHB1_GRP1_EnableClock(LL_AHB1_GRP1_PERIPH_GPIOB);
  /**TIM11 GPIO Configuration
  PB9   ------> TIM11_CH1
  */
  GPIO_InitStruct.Pin = CAMERA_CONTROL_Pin;
  GPIO_InitStruct.Mode = LL_GPIO_MODE_ALTERNATE;
  GPIO_InitStruct.Speed = LL_GPIO_SPEED_FREQ_LOW;
  GPIO_InitStruct.OutputType = LL_GPIO_OUTPUT_PUSHPULL;
  GPIO_InitStruct.Pull = LL_GPIO_PULL_NO;
  GPIO_InitStruct.Alternate = LL_GPIO_AF_3;
  LL_GPIO_Init(CAMERA_CONTROL_GPIO_Port, &GPIO_InitStruct);

}

static void MX_UART4_Init(void)
{

  LL_USART_InitTypeDef USART_InitStruct = {0};

  LL_GPIO_InitTypeDef GPIO_InitStruct = {0};

  /* Peripheral clock enable */
  LL_APB1_GRP1_EnableClock(LL_APB1_GRP1_PERIPH_UART4);

  LL_AHB1_GRP1_EnableClock(LL_AHB1_GRP1_PERIPH_GPIOA);
  /**UART4 GPIO Configuration
  PA0-WKUP   ------> UART4_TX
  PA1   ------> UART4_RX
  */
  GPIO_InitStruct.Pin = LL_GPIO_PIN_0;
  GPIO_InitStruct.Mode = LL_GPIO_MODE_ALTERNATE;
  GPIO_InitStruct.Speed = LL_GPIO_SPEED_FREQ_VERY_HIGH;
  GPIO_InitStruct.OutputType = LL_GPIO_OUTPUT_PUSHPULL;
  GPIO_InitStruct.Pull = LL_GPIO_PULL_NO;
  GPIO_InitStruct.Alternate = LL_GPIO_AF_8;
  LL_GPIO_Init(GPIOA, &GPIO_InitStruct);

  GPIO_InitStruct.Pin = LL_GPIO_PIN_1;
  GPIO_InitStruct.Mode = LL_GPIO_MODE_ALTERNATE;
  GPIO_InitStruct.Speed = LL_GPIO_SPEED_FREQ_VERY_HIGH;
  GPIO_InitStruct.OutputType = LL_GPIO_OUTPUT_PUSHPULL;
  GPIO_InitStruct.Pull = LL_GPIO_PULL_NO;
  GPIO_InitStruct.Alternate = LL_GPIO_AF_8;
  LL_GPIO_Init(GPIOA, &GPIO_InitStruct);

  USART_InitStruct.BaudRate = 115200;
  USART_InitStruct.DataWidth = LL_USART_DATAWIDTH_8B;
  USART_InitStruct.StopBits = LL_USART_STOPBITS_1;
  USART_InitStruct.Parity = LL_USART_PARITY_NONE;
  USART_InitStruct.TransferDirection = LL_USART_DIRECTION_TX_RX;
  USART_InitStruct.HardwareFlowControl = LL_USART_HWCONTROL_NONE;
  USART_InitStruct.OverSampling = LL_USART_OVERSAMPLING_16;
  LL_USART_Init(UART4, &USART_InitStruct);
  LL_USART_ConfigAsyncMode(UART4);
  LL_USART_Enable(UART4);

}

static void MX_UART5_Init(void)
{

  LL_USART_InitTypeDef USART_InitStruct = {0};

  LL_GPIO_InitTypeDef GPIO_InitStruct = {0};

  /* Peripheral clock enable */
  LL_APB1_GRP1_EnableClock(LL_APB1_GRP1_PERIPH_UART5);

  LL_AHB1_GRP1_EnableClock(LL_AHB1_GRP1_PERIPH_GPIOC);
  LL_AHB1_GRP1_EnableClock(LL_AHB1_GRP1_PERIPH_GPIOD);
  /**UART5 GPIO Configuration
  PC12   ------> UART5_TX
  PD2   ------> UART5_RX
  */
  GPIO_InitStruct.Pin = LL_GPIO_PIN_12;
  GPIO_InitStruct.Mode = LL_GPIO_MODE_ALTERNATE;
  GPIO_InitStruct.Speed = LL_GPIO_SPEED_FREQ_VERY_HIGH;
  GPIO_InitStruct.OutputType = LL_GPIO_OUTPUT_PUSHPULL;
  GPIO_InitStruct.Pull = LL_GPIO_PULL_NO;
  GPIO_InitStruct.Alternate = LL_GPIO_AF_8;
  LL_GPIO_Init(GPIOC, &GPIO_InitStruct);

  GPIO_InitStruct.Pin = LL_GPIO_PIN_2;
  GPIO_InitStruct.Mode = LL_GPIO_MODE_ALTERNATE;
  GPIO_InitStruct.Speed = LL_GPIO_SPEED_FREQ_VERY_HIGH;
  GPIO_InitStruct.OutputType = LL_GPIO_OUTPUT_PUSHPULL;
  GPIO_InitStruct.Pull = LL_GPIO_PULL_NO;
  GPIO_InitStruct.Alternate = LL_GPIO_AF_8;
  LL_GPIO_Init(GPIOD, &GPIO_InitStruct);

  USART_InitStruct.BaudRate = 115200;
  USART_InitStruct.DataWidth = LL_USART_DATAWIDTH_8B;
  USART_InitStruct.StopBits = LL_USART_STOPBITS_1;
  USART_InitStruct.Parity = LL_USART_PARITY_NONE;
  USART_InitStruct.TransferDirection = LL_USART_DIRECTION_TX_RX;
  USART_InitStruct.HardwareFlowControl = LL_USART_HWCONTROL_NONE;
  USART_InitStruct.OverSampling = LL_USART_OVERSAMPLING_16;
  LL_USART_Init(UART5, &USART_InitStruct);
  LL_USART_ConfigAsyncMode(UART5);
  LL_USART_Enable(UART5);

}

static void MX_USART1_UART_Init(void)
{

  LL_USART_InitTypeDef USART_InitStruct = {0};

  LL_GPIO_InitTypeDef GPIO_InitStruct = {0};

  /* Peripheral clock enable */
  LL_APB2_GRP1_EnableClock(LL_APB2_GRP1_PERIPH_USART1);

  LL_AHB1_GRP1_EnableClock(LL_AHB1_GRP1_PERIPH_GPIOA);
  /**USART1 GPIO Configuration
  PA9   ------> USART1_TX
  PA10   ------> USART1_RX
  */
  GPIO_InitStruct.Pin = LL_GPIO_PIN_9;
  GPIO_InitStruct.Mode = LL_GPIO_MODE_ALTERNATE;
  GPIO_InitStruct.Speed = LL_GPIO_SPEED_FREQ_VERY_HIGH;
  GPIO_InitStruct.OutputType = LL_GPIO_OUTPUT_PUSHPULL;
  GPIO_InitStruct.Pull = LL_GPIO_PULL_NO;
  GPIO_InitStruct.Alternate = LL_GPIO_AF_7;
  LL_GPIO_Init(GPIOA, &GPIO_InitStruct);

  GPIO_InitStruct.Pin = LL_GPIO_PIN_10;
  GPIO_InitStruct.Mode = LL_GPIO_MODE_ALTERNATE;
  GPIO_InitStruct.Speed = LL_GPIO_SPEED_FREQ_VERY_HIGH;
  GPIO_InitStruct.OutputType = LL_GPIO_OUTPUT_PUSHPULL;
  GPIO_InitStruct.Pull = LL_GPIO_PULL_NO;
  GPIO_InitStruct.Alternate = LL_GPIO_AF_7;
  LL_GPIO_Init(GPIOA, &GPIO_InitStruct);

  USART_InitStruct.BaudRate = 115200;
  USART_InitStruct.DataWidth = LL_USART_DATAWIDTH_8B;
  USART_InitStruct.StopBits = LL_USART_STOPBITS_1;
  USART_InitStruct.Parity = LL_USART_PARITY_NONE;
  USART_InitStruct.TransferDirection = LL_USART_DIRECTION_TX_RX;
  USART_InitStruct.HardwareFlowControl = LL_USART_HWCONTROL_NONE;
  USART_InitStruct.OverSampling = LL_USART_OVERSAMPLING_16;
  LL_USART_Init(USART1, &USART_InitStruct);
  LL_USART_ConfigAsyncMode(USART1);
  LL_USART_Enable(USART1);

}

static void MX_USART2_UART_Init(void)
{

  LL_USART_InitTypeDef USART_InitStruct = {0};

  LL_GPIO_InitTypeDef GPIO_InitStruct = {0};

  /* Peripheral clock enable */
  LL_APB1_GRP1_EnableClock(LL_APB1_GRP1_PERIPH_USART2);

  LL_AHB1_GRP1_EnableClock(LL_AHB1_GRP1_PERIPH_GPIOA);
  /**USART2 GPIO Configuration
  PA2   ------> USART2_TX
  PA3   ------> USART2_RX
  */
  GPIO_InitStruct.Pin = LL_GPIO_PIN_2;
  GPIO_InitStruct.Mode = LL_GPIO_MODE_ALTERNATE;
  GPIO_InitStruct.Speed = LL_GPIO_SPEED_FREQ_VERY_HIGH;
  GPIO_InitStruct.OutputType = LL_GPIO_OUTPUT_PUSHPULL;
  GPIO_InitStruct.Pull = LL_GPIO_PULL_NO;
  GPIO_InitStruct.Alternate = LL_GPIO_AF_7;
  LL_GPIO_Init(GPIOA, &GPIO_InitStruct);

  GPIO_InitStruct.Pin = LL_GPIO_PIN_3;
  GPIO_InitStruct.Mode = LL_GPIO_MODE_ALTERNATE;
  GPIO_InitStruct.Speed = LL_GPIO_SPEED_FREQ_VERY_HIGH;
  GPIO_InitStruct.OutputType = LL_GPIO_OUTPUT_PUSHPULL;
  GPIO_InitStruct.Pull = LL_GPIO_PULL_NO;
  GPIO_InitStruct.Alternate = LL_GPIO_AF_7;
  LL_GPIO_Init(GPIOA, &GPIO_InitStruct);

  USART_InitStruct.BaudRate = 115200;
  USART_InitStruct.DataWidth = LL_USART_DATAWIDTH_8B;
  USART_InitStruct.StopBits = LL_USART_STOPBITS_1;
  USART_InitStruct.Parity = LL_USART_PARITY_NONE;
  USART_InitStruct.TransferDirection = LL_USART_DIRECTION_TX_RX;
  USART_InitStruct.HardwareFlowControl = LL_USART_HWCONTROL_NONE;
  USART_InitStruct.OverSampling = LL_USART_OVERSAMPLING_16;
  LL_USART_Init(USART2, &USART_InitStruct);
  LL_USART_ConfigAsyncMode(USART2);
  LL_USART_Enable(USART2);

}

static void MX_USART3_UART_Init(void)
{

  LL_USART_InitTypeDef USART_InitStruct = {0};

  LL_GPIO_InitTypeDef GPIO_InitStruct = {0};

  /* Peripheral clock enable */
  LL_APB1_GRP1_EnableClock(LL_APB1_GRP1_PERIPH_USART3);

  LL_AHB1_GRP1_EnableClock(LL_AHB1_GRP1_PERIPH_GPIOC);
  /**USART3 GPIO Configuration
  PC10   ------> USART3_TX
  PC11   ------> USART3_RX
  */
  GPIO_InitStruct.Pin = LL_GPIO_PIN_10;
  GPIO_InitStruct.Mode = LL_GPIO_MODE_ALTERNATE;
  GPIO_InitStruct.Speed = LL_GPIO_SPEED_FREQ_VERY_HIGH;
  GPIO_InitStruct.OutputType = LL_GPIO_OUTPUT_PUSHPULL;
  GPIO_InitStruct.Pull = LL_GPIO_PULL_NO;
  GPIO_InitStruct.Alternate = LL_GPIO_AF_7;
  LL_GPIO_Init(GPIOC, &GPIO_InitStruct);

  GPIO_InitStruct.Pin = LL_GPIO_PIN_11;
  GPIO_InitStruct.Mode = LL_GPIO_MODE_ALTERNATE;
  GPIO_InitStruct.Speed = LL_GPIO_SPEED_FREQ_VERY_HIGH;
  GPIO_InitStruct.OutputType = LL_GPIO_OUTPUT_PUSHPULL;
  GPIO_InitStruct.Pull = LL_GPIO_PULL_NO;
  GPIO_InitStruct.Alternate = LL_GPIO_AF_7;
  LL_GPIO_Init(GPIOC, &GPIO_InitStruct);

  USART_InitStruct.BaudRate = 115200;
  USART_InitStruct.DataWidth = LL_USART_DATAWIDTH_8B;
  USART_InitStruct.StopBits = LL_USART_STOPBITS_1;
  USART_InitStruct.Parity = LL_USART_PARITY_NONE;
  USART_InitStruct.TransferDirection = LL_USART_DIRECTION_TX_RX;
  USART_InitStruct.HardwareFlowControl = LL_USART_HWCONTROL_NONE;
  USART_InitStruct.OverSampling = LL_USART_OVERSAMPLING_16;
  LL_USART_Init(USART3, &USART_InitStruct);
  LL_USART_ConfigAsyncMode(USART3);
  LL_USART_Enable(USART3);

}

static void MX_USART6_UART_Init(void)
{

  LL_USART_InitTypeDef USART_InitStruct = {0};

  LL_GPIO_InitTypeDef GPIO_InitStruct = {0};

  /* Peripheral clock enable */
  LL_APB2_GRP1_EnableClock(LL_APB2_GRP1_PERIPH_USART6);

  LL_AHB1_GRP1_EnableClock(LL_AHB1_GRP1_PERIPH_GPIOC);
  /**USART6 GPIO Configuration
  PC6   ------> USART6_TX
  */
  GPIO_InitStruct.Pin = LL_GPIO_PIN_6;
  GPIO_InitStruct.Mode = LL_GPIO_MODE_ALTERNATE;
  GPIO_InitStruct.Speed = LL_GPIO_SPEED_FREQ_VERY_HIGH;
  GPIO_InitStruct.OutputType = LL_GPIO_OUTPUT_OPENDRAIN;
  GPIO_InitStruct.Pull = LL_GPIO_PULL_NO;
  GPIO_InitStruct.Alternate = LL_GPIO_AF_8;
  LL_GPIO_Init(GPIOC, &GPIO_InitStruct);

  USART_InitStruct.BaudRate = 115200;
  USART_InitStruct.DataWidth = LL_USART_DATAWIDTH_8B;
  USART_InitStruct.StopBits = LL_USART_STOPBITS_1;
  USART_InitStruct.Parity = LL_USART_PARITY_NONE;
  USART_InitStruct.TransferDirection = LL_USART_DIRECTION_TX_RX;
  USART_InitStruct.OverSampling = LL_USART_OVERSAMPLING_16;
  LL_USART_Init(USART6, &USART_InitStruct);
  LL_USART_ConfigHalfDuplexMode(USART6);
  LL_USART_Enable(USART6);

}

static void MX_GPIO_Init(void)
{
  LL_EXTI_InitTypeDef EXTI_InitStruct = {0};
  LL_GPIO_InitTypeDef GPIO_InitStruct = {0};

  /* GPIO Ports Clock Enable */
  LL_AHB1_GRP1_EnableClock(LL_AHB1_GRP1_PERIPH_GPIOC);
  LL_AHB1_GRP1_EnableClock(LL_AHB1_GRP1_PERIPH_GPIOH);
  LL_AHB1_GRP1_EnableClock(LL_AHB1_GRP1_PERIPH_GPIOA);
  LL_AHB1_GRP1_EnableClock(LL_AHB1_GRP1_PERIPH_GPIOB);
  LL_AHB1_GRP1_EnableClock(LL_AHB1_GRP1_PERIPH_GPIOD);

  /**/
  LL_GPIO_ResetOutputPin(BEEPER_GPIO_Port, BEEPER_Pin);

  /**/
  LL_GPIO_SetOutputPin(BARO_NSS_GPIO_Port, BARO_NSS_Pin);

  /**/
  LL_GPIO_SetOutputPin(GYRO1_NSS_GPIO_Port, GYRO1_NSS_Pin);

  /**/
  LL_GPIO_SetOutputPin(LED0_GPIO_Port, LED0_Pin);

  /**/
  LL_GPIO_SetOutputPin(SPI2_NSS_GPIO_Port, SPI2_NSS_Pin);

  /**/
  LL_GPIO_SetOutputPin(FLASH_CS_GPIO_Port, FLASH_CS_Pin);

  /**/
  GPIO_InitStruct.Pin = BEEPER_Pin;
  GPIO_InitStruct.Mode = LL_GPIO_MODE_OUTPUT;
  GPIO_InitStruct.Speed = LL_GPIO_SPEED_FREQ_LOW;
  GPIO_InitStruct.OutputType = LL_GPIO_OUTPUT_PUSHPULL;
  GPIO_InitStruct.Pull = LL_GPIO_PULL_NO;
  LL_GPIO_Init(BEEPER_GPIO_Port, &GPIO_InitStruct);

  /**/
  GPIO_InitStruct.Pin = LL_GPIO_PIN_14;
  GPIO_InitStruct.Mode = LL_GPIO_MODE_ANALOG;
  GPIO_InitStruct.Pull = LL_GPIO_PULL_NO;
  LL_GPIO_Init(GPIOC, &GPIO_InitStruct);

  /**/
  GPIO_InitStruct.Pin = BARO_NSS_Pin;
  GPIO_InitStruct.Mode = LL_GPIO_MODE_OUTPUT;
  GPIO_InitStruct.Speed = LL_GPIO_SPEED_FREQ_LOW;
  GPIO_InitStruct.OutputType = LL_GPIO_OUTPUT_PUSHPULL;
  GPIO_InitStruct.Pull = LL_GPIO_PULL_NO;
  LL_GPIO_Init(BARO_NSS_GPIO_Port, &GPIO_InitStruct);

  /**/
  GPIO_InitStruct.Pin = LL_GPIO_PIN_0;
  GPIO_InitStruct.Mode = LL_GPIO_MODE_ANALOG;
  GPIO_InitStruct.Pull = LL_GPIO_PULL_NO;
  LL_GPIO_Init(GPIOC, &GPIO_InitStruct);

  /**/
  GPIO_InitStruct.Pin = GYRO1_NSS_Pin;
  GPIO_InitStruct.Mode = LL_GPIO_MODE_OUTPUT;
  GPIO_InitStruct.Speed = LL_GPIO_SPEED_FREQ_LOW;
  GPIO_InitStruct.OutputType = LL_GPIO_OUTPUT_PUSHPULL;
  GPIO_InitStruct.Pull = LL_GPIO_PULL_NO;
  LL_GPIO_Init(GYRO1_NSS_GPIO_Port, &GPIO_InitStruct);

  /**/
  GPIO_InitStruct.Pin = LED0_Pin;
  GPIO_InitStruct.Mode = LL_GPIO_MODE_OUTPUT;
  GPIO_InitStruct.Speed = LL_GPIO_SPEED_FREQ_LOW;
  GPIO_InitStruct.OutputType = LL_GPIO_OUTPUT_PUSHPULL;
  GPIO_InitStruct.Pull = LL_GPIO_PULL_NO;
  LL_GPIO_Init(LED0_GPIO_Port, &GPIO_InitStruct);

  /**/
  GPIO_InitStruct.Pin = SPI2_NSS_Pin;
  GPIO_InitStruct.Mode = LL_GPIO_MODE_OUTPUT;
  GPIO_InitStruct.Speed = LL_GPIO_SPEED_FREQ_LOW;
  GPIO_InitStruct.OutputType = LL_GPIO_OUTPUT_PUSHPULL;
  GPIO_InitStruct.Pull = LL_GPIO_PULL_NO;
  LL_GPIO_Init(SPI2_NSS_GPIO_Port, &GPIO_InitStruct);

  /**/
  GPIO_InitStruct.Pin = FLASH_CS_Pin;
  GPIO_InitStruct.Mode = LL_GPIO_MODE_OUTPUT;
  GPIO_InitStruct.Speed = LL_GPIO_SPEED_FREQ_LOW;
  GPIO_InitStruct.OutputType = LL_GPIO_OUTPUT_PUSHPULL;
  GPIO_InitStruct.Pull = LL_GPIO_PULL_NO;
  LL_GPIO_Init(FLASH_CS_GPIO_Port, &GPIO_InitStruct);

  /**/
  GPIO_InitStruct.Pin = LL_GPIO_PIN_7;
  GPIO_InitStruct.Mode = LL_GPIO_MODE_ANALOG;
  GPIO_InitStruct.Pull = LL_GPIO_PULL_NO;
  LL_GPIO_Init(GPIOB, &GPIO_InitStruct);

  /**/
  LL_SYSCFG_SetEXTISource(LL_SYSCFG_EXTI_PORTC, LL_SYSCFG_EXTI_LINE4);

  /**/
  EXTI_InitStruct.Line_0_31 = LL_EXTI_LINE_4;
  EXTI_InitStruct.LineCommand = ENABLE;
  EXTI_InitStruct.Mode = LL_EXTI_MODE_IT;
  EXTI_InitStruct.Trigger = LL_EXTI_TRIGGER_RISING;
  LL_EXTI_Init(&EXTI_InitStruct);

  /**/
  LL_GPIO_SetPinPull(GYRO1_EXTI_GPIO_Port, GYRO1_EXTI_Pin, LL_GPIO_PULL_NO);

  /**/
  LL_GPIO_SetPinMode(GYRO1_EXTI_GPIO_Port, GYRO1_EXTI_Pin, LL_GPIO_MODE_INPUT);

}

void Error_Handler(void)
{
}

/************************ (C) COPYRIGHT STMicroelectronics *****END OF FILE****/
